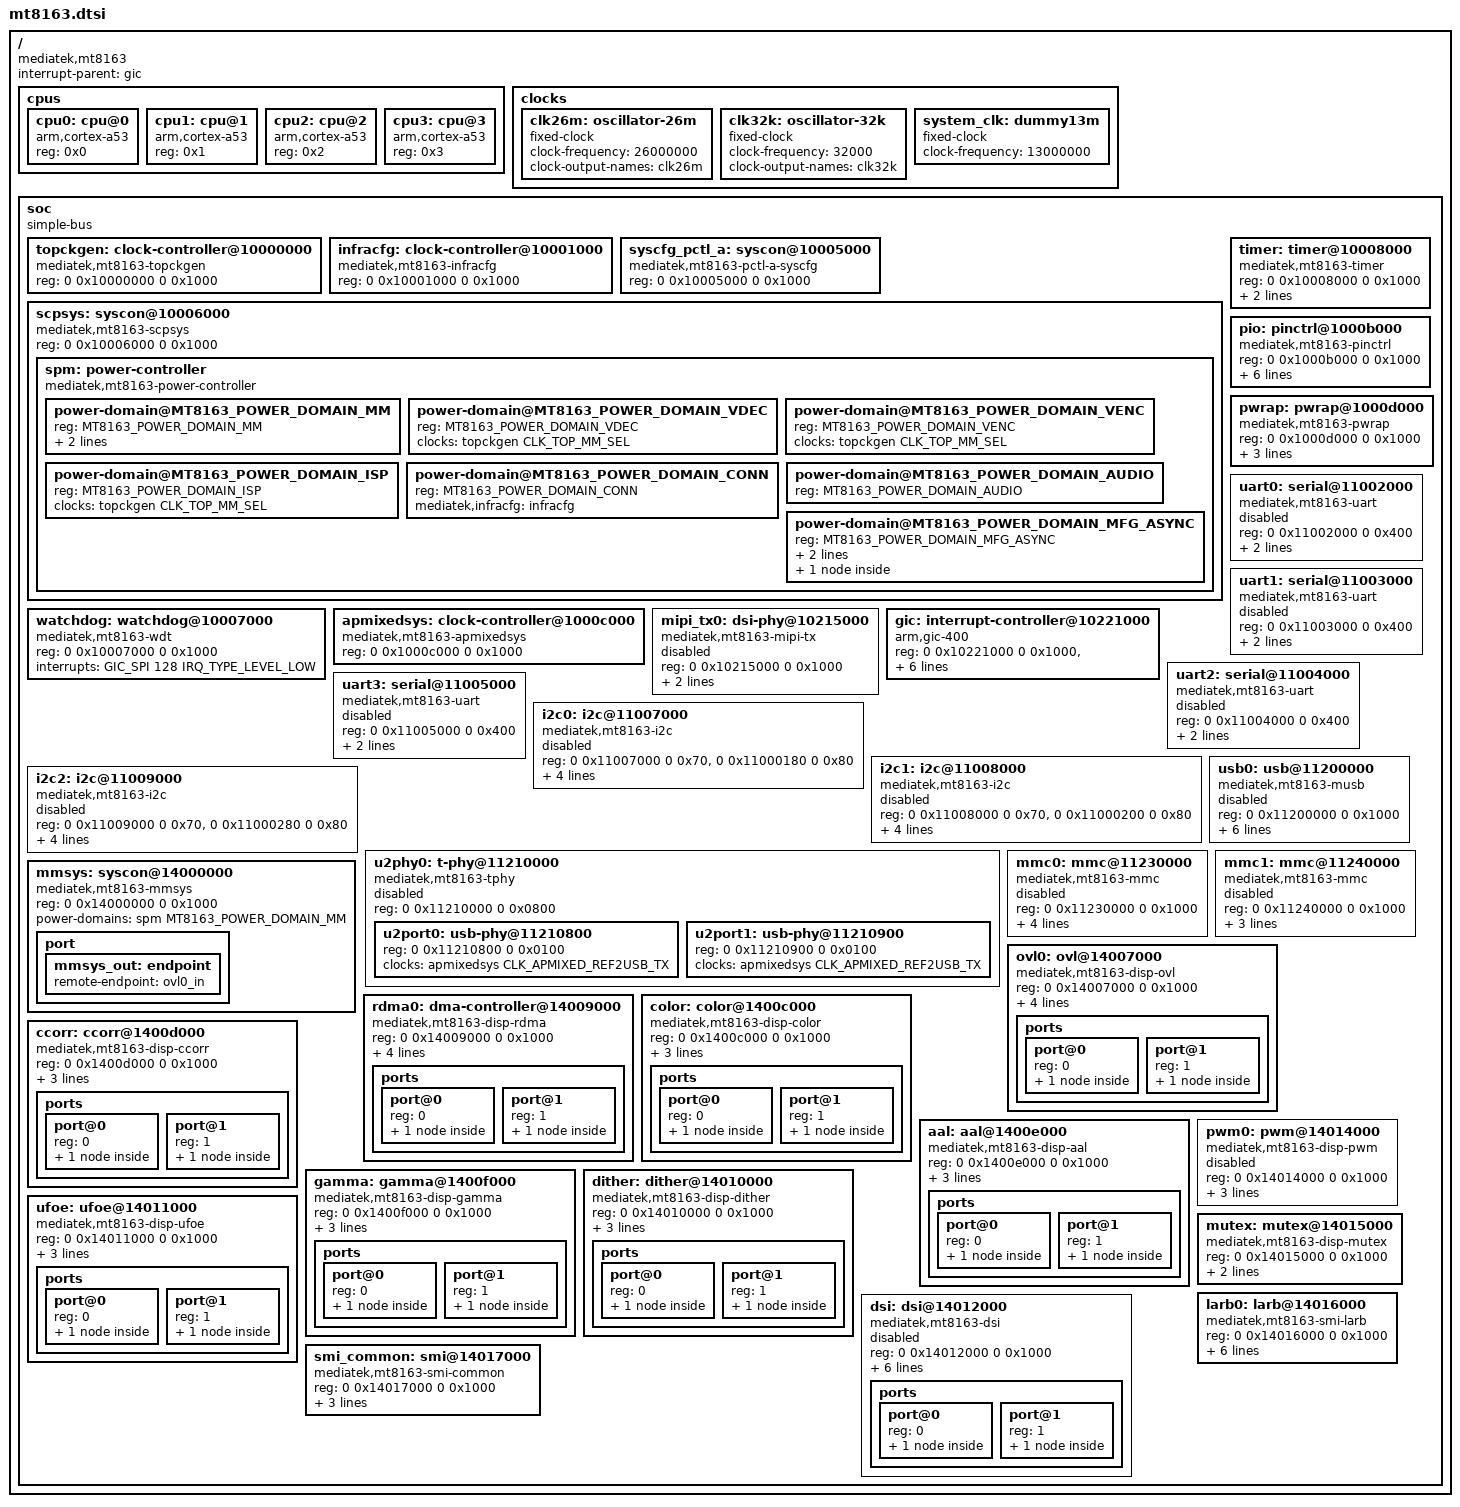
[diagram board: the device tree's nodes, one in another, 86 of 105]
// SPDX-License-Identifier: GPL-2.0-only OR MIT
/*
 * Copyright (c) 2025-2026 Ben Grisdale <bengris32@protonmail.ch>
 */

#include <dt-bindings/interrupt-controller/arm-gic.h>
#include <dt-bindings/phy/phy.h>

#include <dt-bindings/clock/mt8163-clk.h>
#include <dt-bindings/pinctrl/mt65xx.h>
#include <dt-bindings/power/mediatek,mt8163-power-controller.h>
#include <dt-bindings/reset/mediatek,mt8163-mmsys.h>

/ {
	#address-cells = <2>;
	#size-cells = <2>;
	interrupt-parent = <&gic>;
	compatible = "mediatek,mt8163";

	cpus {
		#address-cells = <1>;
		#size-cells = <0>;

		cpu0: cpu@0 {
			device_type = "cpu";
			compatible = "arm,cortex-a53";
			reg = <0x0>;
		};

		cpu1: cpu@1 {
			device_type = "cpu";
			compatible = "arm,cortex-a53";
			reg = <0x1>;
		};

		cpu2: cpu@2 {
			device_type = "cpu";
			compatible = "arm,cortex-a53";
			reg = <0x2>;
		};

		cpu3: cpu@3 {
			device_type = "cpu";
			compatible = "arm,cortex-a53";
			reg = <0x3>;
		};
	};

	clocks {
		clk26m: oscillator-26m {
			compatible = "fixed-clock";
			#clock-cells = <0>;
			clock-frequency = <26000000>;
			clock-output-names = "clk26m";
		};

		clk32k: oscillator-32k {
			compatible = "fixed-clock";
			#clock-cells = <0>;
			clock-frequency = <32000>;
			clock-output-names = "clk32k";
		};

		system_clk: dummy13m {
			compatible = "fixed-clock";
			clock-frequency = <13000000>;
			#clock-cells = <0>;
		};
	};

	soc {
		compatible = "simple-bus";
		#address-cells = <2>;
		#size-cells = <2>;
		ranges;

		topckgen: clock-controller@10000000 {
			compatible = "mediatek,mt8163-topckgen";
			reg = <0 0x10000000 0 0x1000>;
			#clock-cells = <1>;
		};

		infracfg: clock-controller@10001000 {
			compatible = "mediatek,mt8163-infracfg", "syscon";
			reg = <0 0x10001000 0 0x1000>;
			#clock-cells = <1>;
		};

		syscfg_pctl_a: syscon@10005000 {
			compatible = "mediatek,mt8163-pctl-a-syscfg", "syscon";
			reg = <0 0x10005000 0 0x1000>;
		};

		scpsys: syscon@10006000 {
			compatible = "mediatek,mt8163-scpsys", "syscon", "simple-mfd";
			reg = <0 0x10006000 0 0x1000>;

			/* System Power Manager */
			spm: power-controller {
				compatible = "mediatek,mt8163-power-controller";
				#address-cells = <1>;
				#size-cells = <0>;
				#power-domain-cells = <1>;

				/* power domains of the SoC */
				power-domain@MT8163_POWER_DOMAIN_MM {
					reg = <MT8163_POWER_DOMAIN_MM>;
					clocks = <&topckgen CLK_TOP_MM_SEL>;
					clock-names = "mm";
					#power-domain-cells = <0>;
					mediatek,infracfg = <&infracfg>;
				};

				power-domain@MT8163_POWER_DOMAIN_VDEC {
					reg = <MT8163_POWER_DOMAIN_VDEC>;
					clocks = <&topckgen CLK_TOP_MM_SEL>;
					clock-names = "mm";
					#power-domain-cells = <0>;
				};

				power-domain@MT8163_POWER_DOMAIN_VENC {
					reg = <MT8163_POWER_DOMAIN_VENC>;
					clocks = <&topckgen CLK_TOP_MM_SEL>;
					clock-names = "mm";
					#power-domain-cells = <0>;
				};

				power-domain@MT8163_POWER_DOMAIN_ISP {
					reg = <MT8163_POWER_DOMAIN_ISP>;
					clocks = <&topckgen CLK_TOP_MM_SEL>;
					clock-names = "mm";
					#power-domain-cells = <0>;
				};

				power-domain@MT8163_POWER_DOMAIN_CONN {
					reg = <MT8163_POWER_DOMAIN_CONN>;
					#power-domain-cells = <0>;
					mediatek,infracfg = <&infracfg>;
				};

				power-domain@MT8163_POWER_DOMAIN_AUDIO {
					reg = <MT8163_POWER_DOMAIN_AUDIO>;
					#power-domain-cells = <0>;
				};

				power-domain@MT8163_POWER_DOMAIN_MFG_ASYNC {
					reg = <MT8163_POWER_DOMAIN_MFG_ASYNC>;
					clocks = <&topckgen CLK_TOP_MFG_SEL>;
					clock-names = "mfg";
					#address-cells = <1>;
					#size-cells = <0>;
					#power-domain-cells = <1>;
					mediatek,infracfg = <&infracfg>;

					power-domain@MT8163_POWER_DOMAIN_MFG {
						reg = <MT8163_POWER_DOMAIN_MFG>;
						#power-domain-cells = <0>;
					};
				};
			};
		};

		watchdog: watchdog@10007000 {
			compatible = "mediatek,mt8163-wdt", "mediatek,mt6589-wdt";
			reg = <0 0x10007000 0 0x1000>;
			interrupts = <GIC_SPI 128 IRQ_TYPE_LEVEL_LOW>;
		};

		timer: timer@10008000 {
			compatible = "mediatek,mt8163-timer", "mediatek,mt6577-timer";
			reg = <0 0x10008000 0 0x1000>;
			interrupts = <GIC_SPI 152 IRQ_TYPE_LEVEL_LOW>;
			clocks = <&system_clk>;
			clock-names = "system-clk";
		};

		pio: pinctrl@1000b000 {
			compatible = "mediatek,mt8163-pinctrl";
			reg = <0 0x1000b000 0 0x1000>;
			mediatek,pctl-regmap = <&syscfg_pctl_a>;
			gpio-controller;
			#gpio-cells = <2>;
			interrupt-controller;
			#interrupt-cells = <2>;
			interrupts = <GIC_SPI 153 IRQ_TYPE_LEVEL_HIGH>,
				     <GIC_SPI 154 IRQ_TYPE_LEVEL_HIGH>,
				     <GIC_SPI 155 IRQ_TYPE_LEVEL_HIGH>;
		};

		apmixedsys: clock-controller@1000c000 {
			compatible = "mediatek,mt8163-apmixedsys";
			reg = <0 0x1000c000 0 0x1000>;
			#clock-cells = <1>;
		};

		pwrap: pwrap@1000d000 {
			compatible = "mediatek,mt8163-pwrap";
			reg = <0 0x1000d000 0 0x1000>;
			reg-names = "pwrap";
			interrupts = <GIC_SPI 161 IRQ_TYPE_LEVEL_HIGH>;
			clocks = <&topckgen CLK_TOP_PMICSPI_SEL>, <&infracfg CLK_INFRA_PMIC_AP>;
			clock-names = "spi", "wrap";
		};

		mipi_tx0: dsi-phy@10215000 {
			compatible = "mediatek,mt8163-mipi-tx";
			reg = <0 0x10215000 0 0x1000>;
			clocks = <&apmixedsys CLK_APMIXED_MIPI_26M>;
			clock-output-names = "mipi_tx0_pll";
			#clock-cells = <0>;
			#phy-cells = <0>;
			status = "disabled";
		};

		gic: interrupt-controller@10221000 {
			compatible = "arm,gic-400";
			reg = <0 0x10221000 0 0x1000>,
			      <0 0x10222000 0 0x1000>,
			      <0 0x10224000 0 0x2000>,
			      <0 0x10226000 0 0x2000>;
			interrupt-controller;
			#interrupt-cells = <3>;
			interrupt-parent = <&gic>;
			interrupts = <GIC_PPI 9 (GIC_CPU_MASK_SIMPLE(4) | IRQ_TYPE_LEVEL_HIGH)>;
		};

		uart0: serial@11002000 {
			compatible = "mediatek,mt8163-uart", "mediatek,mt6577-uart";
			reg = <0 0x11002000 0 0x400>;
			interrupts = <GIC_SPI 91 IRQ_TYPE_LEVEL_LOW>;
			clocks = <&clk26m>, <&infracfg CLK_INFRA_UART0>;
			clock-names = "baud", "bus";
			status = "disabled";
		};

		uart1: serial@11003000 {
			compatible = "mediatek,mt8163-uart", "mediatek,mt6577-uart";
			reg = <0 0x11003000 0 0x400>;
			interrupts = <GIC_SPI 92 IRQ_TYPE_LEVEL_LOW>;
			clocks = <&clk26m>, <&infracfg CLK_INFRA_UART1>;
			clock-names = "baud", "bus";
			status = "disabled";
		};

		uart2: serial@11004000 {
			compatible = "mediatek,mt8163-uart", "mediatek,mt6577-uart";
			reg = <0 0x11004000 0 0x400>;
			interrupts = <GIC_SPI 93 IRQ_TYPE_LEVEL_LOW>;
			clocks = <&clk26m>, <&infracfg CLK_INFRA_UART2>;
			clock-names = "baud", "bus";
			status = "disabled";
		};

		uart3: serial@11005000 {
			compatible = "mediatek,mt8163-uart", "mediatek,mt6577-uart";
			reg = <0 0x11005000 0 0x400>;
			interrupts = <GIC_SPI 94 IRQ_TYPE_LEVEL_LOW>;
			clocks = <&clk26m>, <&infracfg CLK_INFRA_UART3>;
			clock-names = "baud", "bus";
			status = "disabled";
		};

		i2c0: i2c@11007000 {
			compatible = "mediatek,mt8163-i2c", "mediatek,mt7622-i2c";
			reg = <0 0x11007000 0 0x70>, <0 0x11000180 0 0x80>;
			interrupts = <GIC_SPI 84 IRQ_TYPE_LEVEL_LOW>;
			clock-div = <10>;
			clocks = <&infracfg CLK_INFRA_I2C0>, <&infracfg CLK_INFRA_AP_DMA>;
			clock-names = "main", "dma";
			#address-cells = <1>;
			#size-cells = <0>;
			status = "disabled";
		};

		i2c1: i2c@11008000 {
			compatible = "mediatek,mt8163-i2c", "mediatek,mt7622-i2c";
			reg = <0 0x11008000 0 0x70>, <0 0x11000200 0 0x80>;
			interrupts = <GIC_SPI 85 IRQ_TYPE_LEVEL_LOW>;
			clock-div = <10>;
			clocks = <&infracfg CLK_INFRA_I2C1>, <&infracfg CLK_INFRA_AP_DMA>;
			clock-names = "main", "dma";
			#address-cells = <1>;
			#size-cells = <0>;
			status = "disabled";
		};

		i2c2: i2c@11009000 {
			compatible = "mediatek,mt8163-i2c", "mediatek,mt7622-i2c";
			reg = <0 0x11009000 0 0x70>, <0 0x11000280 0 0x80>;
			interrupts = <GIC_SPI 86 IRQ_TYPE_LEVEL_LOW>;
			clock-div = <10>;
			clocks = <&infracfg CLK_INFRA_I2C2>, <&infracfg CLK_INFRA_AP_DMA>;
			clock-names = "main", "dma";
			#address-cells = <1>;
			#size-cells = <0>;
			status = "disabled";
		};

		usb0: usb@11200000 {
			compatible = "mediatek,mt8163-musb", "mediatek,mtk-musb";
			reg = <0 0x11200000 0 0x1000>;
			interrupts = <GIC_SPI 72 IRQ_TYPE_LEVEL_LOW>;
			interrupt-names = "mc";
			phys = <&u2port0 PHY_TYPE_USB2>;
			dr_mode = "otg";
			clocks = <&infracfg CLK_INFRA_USB>,
				 <&infracfg CLK_INFRA_USB_MCU>,
				 <&apmixedsys CLK_APMIXED_UNIVPLL>;
			clock-names = "main", "mcu", "univpll";
			status = "disabled";
		};

		u2phy0: t-phy@11210000 {
			compatible = "mediatek,mt8163-tphy", "mediatek,generic-tphy-v1";
			reg = <0 0x11210000 0 0x0800>;
			#address-cells = <2>;
			#size-cells = <2>;
			ranges;
			status = "disabled";

			u2port0: usb-phy@11210800 {
				reg = <0 0x11210800 0 0x0100>;
				clocks = <&apmixedsys CLK_APMIXED_REF2USB_TX>;
				clock-names = "ref";
				#phy-cells = <1>;
			};

			u2port1: usb-phy@11210900 {
				reg = <0 0x11210900 0 0x0100>;
				clocks = <&apmixedsys CLK_APMIXED_REF2USB_TX>;
				clock-names = "ref";
				#phy-cells = <1>;
			};
		};

		mmc0: mmc@11230000 {
			compatible = "mediatek,mt8163-mmc", "mediatek,mt7623-mmc";
			reg = <0 0x11230000 0 0x1000>;
			interrupts = <GIC_SPI 79 IRQ_TYPE_LEVEL_LOW>;
			clocks = <&infracfg CLK_INFRA_MSDC0>,
				 <&topckgen CLK_TOP_MSDC30_0_SEL>,
				 <&infracfg CLK_INFRA_MSDC3>;
			clock-names = "source", "hclk", "src_clk_cg";
			status = "disabled";
		};

		mmc1: mmc@11240000 {
			compatible = "mediatek,mt8163-mmc", "mediatek,mt7623-mmc";
			reg = <0 0x11240000 0 0x1000>;
			interrupts = <GIC_SPI 80 IRQ_TYPE_LEVEL_LOW>;
			clocks = <&infracfg CLK_INFRA_MSDC1>,
				 <&topckgen CLK_TOP_MSDC30_1_SEL>;
			clock-names = "source", "hclk";
			status = "disabled";
		};

		mmsys: syscon@14000000 {
			compatible = "mediatek,mt8163-mmsys", "syscon";
			reg = <0 0x14000000 0 0x1000>;
			power-domains = <&spm MT8163_POWER_DOMAIN_MM>;
			#clock-cells = <1>;
			#reset-cells = <1>;

			port {
				mmsys_out: endpoint {
					remote-endpoint = <&ovl0_in>;
				};
			};
		};

		ovl0: ovl@14007000 {
			compatible = "mediatek,mt8163-disp-ovl", "mediatek,mt8173-disp-ovl";
			reg = <0 0x14007000 0 0x1000>;
			interrupts = <GIC_SPI 184 IRQ_TYPE_LEVEL_LOW>;
			power-domains = <&spm MT8163_POWER_DOMAIN_MM>;
			clocks = <&mmsys CLK_MM_DISP_OVL0>;
			resets = <&mmsys MT8163_MMSYS_RST_DISP_OVL0>;

			ports {
				#address-cells = <1>;
				#size-cells = <0>;

				port@0 {
					reg = <0>;

					ovl0_in: endpoint {
						remote-endpoint = <&mmsys_out>;
					};
				};

				port@1 {
					reg = <1>;

					ovl0_out: endpoint {
						remote-endpoint = <&color_in>;
					};
				};
			};
		};

		rdma0: dma-controller@14009000 {
			compatible = "mediatek,mt8163-disp-rdma", "mediatek,mt8173-disp-rdma";
			reg = <0 0x14009000 0 0x1000>;
			interrupts = <GIC_SPI 186 IRQ_TYPE_LEVEL_LOW>;
			power-domains = <&spm MT8163_POWER_DOMAIN_MM>;
			clocks = <&mmsys CLK_MM_DISP_RDMA0>;
			resets = <&mmsys MT8163_MMSYS_RST_DISP_RDMA0>;

			ports {
				#address-cells = <1>;
				#size-cells = <0>;

				port@0 {
					reg = <0>;

					rdma0_in: endpoint {
						remote-endpoint = <&dither_out>;
					};
				};

				port@1 {
					reg = <1>;

					rdma0_out: endpoint {
						remote-endpoint = <&ufoe_in>;
					};
				};
			};
		};

		color: color@1400c000 {
			compatible = "mediatek,mt8163-disp-color", "mediatek,mt8173-disp-color";
			reg = <0 0x1400c000 0 0x1000>;
			interrupts = <GIC_SPI 189 IRQ_TYPE_LEVEL_LOW>;
			power-domains = <&spm MT8163_POWER_DOMAIN_MM>;
			clocks = <&mmsys CLK_MM_DISP_COLOR>;

			ports {
				#address-cells = <1>;
				#size-cells = <0>;

				port@0 {
					reg = <0>;

					color_in: endpoint {
						remote-endpoint = <&ovl0_out>;
					};
				};

				port@1 {
					reg = <1>;

					color_out: endpoint {
						remote-endpoint = <&ccorr_in>;
					};
				};
			};
		};

		ccorr: ccorr@1400d000 {
			compatible = "mediatek,mt8163-disp-ccorr", "mediatek,mt8192-disp-ccorr";
			reg = <0 0x1400d000 0 0x1000>;
			interrupts = <GIC_SPI 190 IRQ_TYPE_LEVEL_LOW>;
			power-domains = <&spm MT8163_POWER_DOMAIN_MM>;
			clocks = <&mmsys CLK_MM_DISP_CCORR>;

			ports {
				#address-cells = <1>;
				#size-cells = <0>;

				port@0 {
					reg = <0>;

					ccorr_in: endpoint {
						remote-endpoint = <&color_out>;
					};
				};

				port@1 {
					reg = <1>;

					ccorr_out: endpoint {
						remote-endpoint = <&aal_in>;
					};
				};
			};
		};

		aal: aal@1400e000 {
			compatible = "mediatek,mt8163-disp-aal", "mediatek,mt8183-disp-aal";
			reg = <0 0x1400e000 0 0x1000>;
			interrupts = <GIC_SPI 191 IRQ_TYPE_LEVEL_LOW>;
			power-domains = <&spm MT8163_POWER_DOMAIN_MM>;
			clocks = <&mmsys CLK_MM_DISP_AAL>;

			ports {
				#address-cells = <1>;
				#size-cells = <0>;

				port@0 {
					reg = <0>;

					aal_in: endpoint {
						remote-endpoint = <&ccorr_out>;
					};
				};

				port@1 {
					reg = <1>;

					aal_out: endpoint {
						remote-endpoint = <&gamma_in>;
					};
				};
			};
		};

		gamma: gamma@1400f000 {
			compatible = "mediatek,mt8163-disp-gamma";
			reg = <0 0x1400f000 0 0x1000>;
			interrupts = <GIC_SPI 192 IRQ_TYPE_LEVEL_LOW>;
			power-domains = <&spm MT8163_POWER_DOMAIN_MM>;
			clocks = <&mmsys CLK_MM_DISP_GAMMA>;

			ports {
				#address-cells = <1>;
				#size-cells = <0>;

				port@0 {
					reg = <0>;

					gamma_in: endpoint {
						remote-endpoint = <&aal_out>;
					};
				};

				port@1 {
					reg = <1>;

					gamma_out: endpoint {
						remote-endpoint = <&dither_in>;
					};
				};
			};
		};

		dither: dither@14010000 {
			compatible = "mediatek,mt8163-disp-dither", "mediatek,mt8183-disp-dither";
			reg = <0 0x14010000 0 0x1000>;
			interrupts = <GIC_SPI 193 IRQ_TYPE_LEVEL_LOW>;
			power-domains = <&spm MT8163_POWER_DOMAIN_MM>;
			clocks = <&mmsys CLK_MM_DISP_DITHER>;

			ports {
				#address-cells = <1>;
				#size-cells = <0>;

				port@0 {
					reg = <0>;

					dither_in: endpoint {
						remote-endpoint = <&gamma_out>;
					};
				};

				port@1 {
					reg = <1>;

					dither_out: endpoint {
						remote-endpoint = <&rdma0_in>;
					};
				};
			};
		};

		ufoe: ufoe@14011000 {
			compatible = "mediatek,mt8163-disp-ufoe", "mediatek,mt8173-disp-ufoe";
			reg = <0 0x14011000 0 0x1000>;
			interrupts = <GIC_SPI 194 IRQ_TYPE_LEVEL_LOW>;
			power-domains = <&spm MT8163_POWER_DOMAIN_MM>;
			clocks = <&mmsys CLK_MM_DISP_UFOE>;

			ports {
				#address-cells = <1>;
				#size-cells = <0>;

				port@0 {
					reg = <0>;

					ufoe_in: endpoint {
						remote-endpoint = <&rdma0_out>;
					};
				};

				port@1 {
					reg = <1>;

					ufoe_out: endpoint {
						remote-endpoint = <&dsi_in>;
					};
				};
			};
		};

		dsi: dsi@14012000 {
			compatible = "mediatek,mt8163-dsi";
			reg = <0 0x14012000 0 0x1000>;
			interrupts = <GIC_SPI 195 IRQ_TYPE_LEVEL_LOW>;
			power-domains = <&spm MT8163_POWER_DOMAIN_MM>;
			clocks = <&mmsys CLK_MM_DSI_ENGINE>,
				 <&mmsys CLK_MM_DSI_DIGITAL>,
				 <&mipi_tx0>;
			clock-names = "engine", "digital", "hs";
			resets = <&mmsys MT8163_MMSYS_RST_DSI>;
			phys = <&mipi_tx0>;
			phy-names = "dphy";
			#address-cells = <1>;
			#size-cells = <0>;
			status = "disabled";

			ports {
				#address-cells = <1>;
				#size-cells = <0>;

				port@0 {
					reg = <0>;

					dsi_in: endpoint {
						remote-endpoint = <&ufoe_out>;
					};
				};

				port@1 {
					reg = <1>;

					dsi_out: endpoint {
					};
				};
			};
		};

		pwm0: pwm@14014000 {
			compatible = "mediatek,mt8163-disp-pwm",
				     "mediatek,mt8173-disp-pwm";
			reg = <0 0x14014000 0 0x1000>;
			#pwm-cells = <2>;
			power-domains = <&spm MT8163_POWER_DOMAIN_MM>;
			clocks = <&mmsys CLK_MM_DISP_PWM_26M>,
				 <&mmsys CLK_MM_DISP_PWM_MM>;
			clock-names = "main", "mm";
			status = "disabled";
		};

		mutex: mutex@14015000 {
			compatible = "mediatek,mt8163-disp-mutex";
			reg = <0 0x14015000 0 0x1000>;
			interrupts = <GIC_SPI 177 IRQ_TYPE_LEVEL_LOW>;
			power-domains = <&spm MT8163_POWER_DOMAIN_MM>;
		};

		larb0: larb@14016000 {
			compatible = "mediatek,mt8163-smi-larb", "mediatek,mt8173-smi-larb";
			reg = <0 0x14016000 0 0x1000>;
			interrupts = <GIC_SPI 205 IRQ_TYPE_LEVEL_LOW>;
			mediatek,smi = <&smi_common>;
			mediatek,larb-id = <0>;
			clocks = <&mmsys CLK_MM_SMI_LARB0>,
				 <&mmsys CLK_MM_SMI_LARB0>;
			clock-names = "apb", "smi";
			power-domains = <&spm MT8163_POWER_DOMAIN_MM>;
		};

		smi_common: smi@14017000 {
			compatible = "mediatek,mt8163-smi-common";
			reg = <0 0x14017000 0 0x1000>;
			clocks = <&mmsys CLK_MM_SMI_COMMON>,
				 <&mmsys CLK_MM_SMI_COMMON>;
			clock-names = "apb", "smi";
			power-domains = <&spm MT8163_POWER_DOMAIN_MM>;
		};
	};
};
